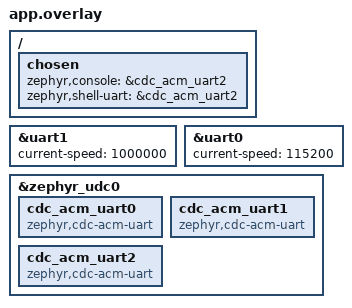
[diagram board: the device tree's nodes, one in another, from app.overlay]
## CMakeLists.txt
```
# SPDX-License-Identifier: MIT
#
# DECT mesh BLE relay (Thingy:91 X nRF5340): L2CAP CoC <-> inter-chip UART.
# Consumes 9P4Z as a Zephyr module (9P session pools, sysfs, DFU):
#   west build -b thingy91x/nrf5340/cpuapp . --sysbuild -- \
#     -DZEPHYR_EXTRA_MODULES=/Users/jrsharp/src/9p4z

cmake_minimum_required(VERSION 3.20.0)

find_package(Zephyr REQUIRED HINTS $ENV{ZEPHYR_BASE})
project(dect_relay)

target_sources(app PRIVATE src/main.c src/aether_conv_transport.c)
```

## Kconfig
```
# dect_relay — nRF5340 9P/USB aggregator application configuration

menu "dect_relay (nRF5340 9P/USB aggregator)"

# Per-module log level. Defaults to LOG_DEFAULT_LEVEL (INF), at which the verbose
# 9151-link diagnostics (mesh RX deliver / post-Tversion / post-Twalk / walk
# hexdump) -- which are LOG_DBG -- compile out entirely. Set
# CONFIG_DECT_RELAY_LOG_LEVEL_DBG=y to bring them back when debugging the link.
module = DECT_RELAY
module-str = dect_relay
source "$(ZEPHYR_BASE)/subsys/logging/Kconfig.template.log_config"

menu "Zephyr Kernel"
source "Kconfig.zephyr"
endmenu

endmenu
```

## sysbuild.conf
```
# Build the nRF5340 network-core image as a Bluetooth HCI controller (IPC radio),
# so the application core's BLE host has a controller to talk to.
SB_CONFIG_NETCORE_IPC_RADIO=y
SB_CONFIG_NETCORE_IPC_RADIO_BT_HCI_IPC=y
```

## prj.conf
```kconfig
# nRF5340 BLE relay: a transparent byte pump between a Bluetooth LE L2CAP
# connection-oriented channel (no custom GATT) and the inter-chip UART (uart1)
# carrying the nRF9151's 9P /net/aether server.

# --- Bluetooth LE peripheral + L2CAP CoC -----------------------------------
CONFIG_BT=y
CONFIG_BT_PERIPHERAL=y
CONFIG_BT_DEVICE_NAME="DECTstrous GW"
# Legacy connectable advertising: 9P-over-L2CAP clients (iOS scanner, 9p4z
# l2cap_client) discover the gateway via the 9PIS service UUID, which fits the
# 31-byte legacy AD (flags + 128-bit UUID = 21 B). No extended adv -> no net-core
# controller change, so this rides the app-core dev/fw5340 OTA.
# L2CAP CoC requires the SMP module to be present (BT_L2CAP_DYNAMIC_CHANNEL
# depends on BT_SMP). The link itself is left open (sec_level L1); the 9PIS
# chars and the 9P service need no pairing/bonding (per the gateway brief).
CONFIG_BT_SMP=y
CONFIG_BT_BONDABLE=n
CONFIG_BT_L2CAP_DYNAMIC_CHANNEL=y
# L2CAP SDU MTU. NCS clamps this to ~65 if pushed past what the ACL buffers allow
# (and treats the clamp as a fatal Kconfig warning), so keep it at 512 -- plenty
# for a /net/aether datagram (~471 B 9P message). The 9PIS transport_info still
# advertises mtu=4096 as the service ceiling; the CoC channel negotiates the real
# MTU (512) at connect, so the client just over-allocates its RX buffer. The RX
# side sets a matching rx.mtu + alloc_buf in 9p4z session_pool_l2cap.
CONFIG_BT_L2CAP_TX_MTU=512
CONFIG_BT_BUF_ACL_RX_SIZE=251
CONFIG_BT_BUF_ACL_TX_SIZE=251
CONFIG_BT_DATA_LEN_UPDATE=y
CONFIG_BT_AUTO_PHY_UPDATE=y

# --- 9P Information Service (9PIS) GATT + PSM ------------------------------
# The 9PIS GATT service lets clients read the PSM/MTU/features and connect with
# zero config; the service UUID is advertised so they can filter on it. PSM
# 0x0080 (=128) is the value clients expect for the 9P L2CAP service.
CONFIG_NINEP_GATT_9PIS=y
CONFIG_NINEP_L2CAP_PSM=0x0080

# --- Inter-chip UART (interrupt-driven) + ring buffer ----------------------
CONFIG_SERIAL=y
CONFIG_UART_INTERRUPT_DRIVEN=y
CONFIG_RING_BUFFER=y
# GPIO: we drive the 9151's reset line (P1.07) to bring it out of reset at boot.
CONFIG_GPIO=y

# --- USB CDC ACM: surface the nRF9151 console (its uart0 -> our uart0) over USB
# so the host can drive the 9151 shell (dect bands/info/cad) and read mesh logs.
# Descriptors mirror the stock connectivity_bridge so existing host tooling/udev
# rules recognize it (Nordic VID 0x1915 / "Thingy:91 X UART" PID). --------------
CONFIG_USB_DEVICE_STACK=y
CONFIG_USB_DEVICE_MANUFACTURER="Nordic Semiconductor"
CONFIG_USB_DEVICE_PRODUCT="DECT Aether Relay"
CONFIG_USB_DEVICE_VID=0x1915
CONFIG_USB_DEVICE_PID=0x910A
CONFIG_USB_MAX_POWER=250
CONFIG_USB_CDC_ACM=y
CONFIG_USB_CDC_ACM_RINGBUF_SIZE=2048
# Composite: 3 CDC ACM ports (9151 console / 9P / 5340 console). More USB
# transfer slots so the 3 endpoints don't exhaust the pool (was flooding
# "usb_transfer: No transfer slot available").
CONFIG_USB_COMPOSITE_DEVICE=y
CONFIG_USB_MAX_NUM_TRANSFERS=8

# --- 9P server: firmware-as-files over the 2nd USB CDC (Phase 2) -------------
# A 9p4z server on cdc_acm_uart1 exposing an MCUboot DFU node so the host can
# `9p write /dev/fw5340` to self-update the 5340 in situ. Phase 3 adds a client
# link to the 9151 + union_fs to re-export /dev/fw9151 + /net/aether here too.
CONFIG_NINEP=y
CONFIG_NINEP_SERVER=y
# DTR-gated session pool over CDC-ACM: a fresh 9P session (RX state + fid
# namespace) per host open/close, so the server no longer wedges when a stream
# client reconnects. Each session's recv handler runs on a dedicated work queue
# (interrupt-driven RX feeds it), not the UART ISR. Shares fs_ops with the L2CAP
# session pool below for a multi-transport re-export server.
CONFIG_NINEP_SESSION_POOL_UART=y
# Re-export the SAME fw_sysfs over BLE L2CAP CoC as well (PSM RELAY_PSM). Same
# /dev tree, second transport -- 9P's transport-agnostic story, made literal.
# (Depends on BT_L2CAP_DYNAMIC_CHANNEL, already enabled above.)
CONFIG_NINEP_TRANSPORT_L2CAP=y
# --- 9P CLIENT to the 9151 over uart1 (the aggregator link) -----------------
# The 5340 is a 9P client to the 9151's server (its uart0 <-> our uart1), so it
# can re-export the 9151's /dev/firmware as /dev/fw9151. RX uses DEFERRED_RX
# (interrupt ISR -> byte ring -> framer thread), NOT the old POLLING mode: that
# was a lowest-priority busy-poll that got STARVED under BLE+USB+chat load, so it
# missed uart1 RX bytes -> the 9P framing desynced -> the host saw "read failed" /
# one-sided chat / flaky sessions. With DEFERRED_RX the ISR catches every byte
# into the ring (hardware-priority), and only framer-thread lag (absorbed by the
# ring) can ever drop -- the same fix the 9151 side already made. recv_cb still
# runs in thread context (the framer thread), so the condvar-broadcast rule holds.
CONFIG_NINEP_CLIENT=y
CONFIG_NINEP_TRANSPORT_UART=y
CONFIG_NINEP_UART_DEFERRED_RX=y
CONFIG_NINEP_UART_POLLING_STACK_SIZE=8192
# Ring >= one max message (msize 8192) + slack, so a full pipelined reply can be
# absorbed while the framer thread is briefly preempted.
CONFIG_NINEP_UART_DEFERRED_RX_RING_SIZE=12288
CONFIG_NINEP_DFU=y
# Transparent proxy backend: re-export the 9151's dynamic /net/aether datagram
# tree (clone/ctl/data conversations) as a local mount, so host/L2CAP 9P clients
# reach it through the same server that serves /dev/fw9151. Each host fid keeps a
# persistent 1:1 mapping to a 9151 client fid (clone allocates upstream on walk).
CONFIG_NINEP_REMOTE_FS=y
# Async (worker-dispatched) reads: a host read of /net/aether `data` forwards
# over the mesh client and blocks until a datagram arrives; without this it would
# stall the session-pool processing thread (freezing the USB 9P server for other
# requests). The worker runs the forwarding client_read off that thread. Its
# stack must hold ninep_client_read's ~2KB reply buffer, so widen it to 4096.
CONFIG_NINEP_SERVER_ASYNC_READ=y
CONFIG_NINEP_SERVER_ASYNC_READ_WORKERS=4
CONFIG_NINEP_SERVER_ASYNC_READ_STACK=4096
# Headroom: each re-exported /net/aether fid consumes one mesh-client fid (on top
# of the base-path fid + the OTA write fid), so widen the client fid pool.
CONFIG_NINEP_MAX_FIDS=48
# Server-side fid table. The default (32) is exhausted by 9pfuse: macOS holds a
# fid per FUSE-cached inode and re-looks-up files as entry_valid lapses WITHOUT
# ever sending Forget, so held fids accumulate (~1 per read) until Twalk hits
# "cannot allocate newfid" (which 9pfuse surfaces as "Result too large" after
# ~28 reads). Stock `9p` clunks promptly and never gets near this. Give a big
# pool so realistic 9pfuse sessions don't exhaust before macOS reclaims inodes.
CONFIG_NINEP_SERVER_MAX_FIDS=256
CONFIG_NINEP_MAX_MESSAGE_SIZE=8192
# MCUboot image management for DFU (the bootloader itself comes from sysbuild).
CONFIG_IMG_MANAGER=y
# Erase the secondary slot a page at a time as the image streams in, NOT one
# long up-front erase. On nRF53 a flash erase stalls instruction fetch, so the
# whole-slot erase blocked USB for seconds -> the relay fell into MCUboot
# mid-write. Progressive erase also makes flash_img own the (correct) secondary.
CONFIG_IMG_ERASE_PROGRESSIVELY=y
CONFIG_STREAM_FLASH=y
CONFIG_FLASH=y
CONFIG_FLASH_MAP=y
CONFIG_REBOOT=y

# --- 5340 console -> USB CDC (cdc_acm_uart2); RTT kept as a 2nd log backend --
# Console + log go to cdc_acm_uart2 (chosen zephyr,console). Logs ALSO go to RTT
# as a fallback (DK path + the early boot before USB enumerates). So the relay's
# own log is finally readable over USB -- no DK/RTT required to debug it.
CONFIG_UART_CONSOLE=y
CONFIG_RTT_CONSOLE=n
CONFIG_UART_LINE_CTRL=y
CONFIG_LOG=y
# The interactive shell now owns cdc_acm_uart2 (zephyr,shell-uart), so logs go out
# via the SHELL's log backend (CONFIG_SHELL_LOG_BACKEND, default y) interleaved with
# the prompt. Drop the standalone UART log backend or every line double-prints on
# CDC2. RTT stays as a 2nd backend (J-Link + early boot before the shell is up).
CONFIG_LOG_BACKEND_UART=n
CONFIG_USE_SEGGER_RTT=y
CONFIG_LOG_BACKEND_RTT=y
# Verbose 9151-link diagnostics (mesh RX deliver / post-Tversion / post-Twalk /
# walk hexdump) are LOG_DBG and compile out at the default INF level. Uncomment
# to bring them back when debugging the uart1 link (see app Kconfig):
# CONFIG_DECT_RELAY_LOG_LEVEL_DBG=y

# Boot-banner app name (default was "My Application"); version comes from VERSION.
CONFIG_NCS_APPLICATION_BOOT_BANNER_STRING="DECTstrous Relay"
# MCUboot image version so a self-OTA swap is verifiable (current/pending in
# /dev/fw5340); keep in sync with VERSION above.
CONFIG_MCUBOOT_IMGTOOL_SIGN_VERSION="0.38.31+0"

# --- Memfault: coredump + reboot-reason capture, exported over the 5340 console -
# The relay should report to the Memfault fleet, and right now this is how we catch
# the DFU-write crash: Memfault captures a coredump (faulting PC + stack) and the
# reboot reason across the reset. On the next boot, `mflt export` dumps them as
# base64 chunks over this console (cdc2) for offline decode / upload.
CONFIG_MEMFAULT=y
CONFIG_MEMFAULT_NCS_PROJECT_KEY=""
CONFIG_MEMFAULT_NCS_FW_TYPE="dect-relay-5340"
# Report the real build version (VERSION file) -- leave FW_VERSION unset so it
# defaults to $(APP_VERSION_TWEAK_STRING) instead of a hardcoded string.
CONFIG_MEMFAULT_NCS_FW_VERSION_STATIC=y
CONFIG_MEMFAULT_NCS_HW_VERSION="thingy91x"
CONFIG_MEMFAULT_NCS_DEVICE_ID_RUNTIME=y
# Emit a heartbeat (metrics chunk) every 60s like the 9151, so the relay device
# reports regularly instead of on the NCS default ~1h interval.
CONFIG_MEMFAULT_METRICS_HEARTBEAT_INTERVAL_SECS=60
# RAM-backed coredump survives the warm (fault) reset; reboot reason is read from
# RESETREAS at boot, so it survives even a brownout.
CONFIG_MEMFAULT_RAM_BACKED_COREDUMP=y
# Interactive Zephyr shell + the `mflt` debug shell (provides `mflt export`).
CONFIG_SHELL=y
CONFIG_MEMFAULT_SHELL=y

# --- System ----------------------------------------------------------------
# 9P server TX buffer (NINEP_MAX_MESSAGE_SIZE=8192) is heap-allocated; the
# re-export will add a client too. 16K ENOMEM'd it alongside BT+USB -> give room.
CONFIG_HEAP_MEM_POOL_SIZE=49152
CONFIG_MAIN_STACK_SIZE=2048
# DFU-write lockup debug: HW_STACK_PROTECTION guards thread stacks but the
# MSP/ISR stack was unguarded -> an overflow during the deep flash write escalated
# to a CPU lockup (RESETREAS bit4) with no handler/coredump. Guard the main stack
# so it faults (Memfault catches it) instead, and give the 9P work queue room for
# the flash_img -> soc_flash_nrf chain.
CONFIG_MPU_STACK_GUARD=y
CONFIG_NINEP_SESSION_PROC_STACK_SIZE=16384
```

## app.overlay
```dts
/*
 * Relay overlay. Inter-chip links to the nRF9151: uart1 (9P /net/aether) and
 * uart0 (the 9151's console/shell). Three USB CDC ACM ports front it all:
 *   cdc0 = 9151 console   cdc1 = 9P   cdc2 = the 5340's OWN console.
 */

/ {
	chosen {
		zephyr,console = &cdc_acm_uart2;     /* relay's own log -> USB (CDC2) */
		zephyr,shell-uart = &cdc_acm_uart2;  /* interactive shell on CDC2 too
						      * (board default was &rtt0 = J-Link only) */
	};
};

/* 9151 9P transport (its uart1) -> BLE L2CAP. */
&uart1 {
	status = "okay";
	/* Inter-chip 9P link to the nRF9151. 1 Mbps -- MUST match the 9151 side
	 * (dect_mesh app.overlay); flash both together or the link breaks. */
	current-speed = <1000000>;
};

/* 9151 console/shell (its uart0) -> USB CDC ACM. */
&uart0 {
	status = "okay";
	current-speed = <115200>;
};

/* Composite USB: THREE CDC ACM ports (max on nRF5340: 2 IN + 1 OUT eps each).
 *   cdc_acm_uart0 -> 9151 console/shell (byte-pump from uart0)
 *   cdc_acm_uart1 -> 9P (aggregator re-export server / pump to the 9151)
 *   cdc_acm_uart2 -> the 5340's OWN console (this relay's log over USB)
 * The board defines &usbd (nordic,nrf-usbd); we add the CDC ACM functions. */
&zephyr_udc0 {
	cdc_acm_uart0: cdc_acm_uart0 {
		compatible = "zephyr,cdc-acm-uart";
	};
	cdc_acm_uart1: cdc_acm_uart1 {
		compatible = "zephyr,cdc-acm-uart";
	};
	cdc_acm_uart2: cdc_acm_uart2 {
		compatible = "zephyr,cdc-acm-uart";
	};
};
```

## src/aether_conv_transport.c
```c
/*
 * aether_conv_transport -- see aether_conv_transport.h and doc/MESH_REMOTE_MOUNT.md.
 *
 * Layering (bottom to top):
 *   carrier mesh_client (UART) -> 9151 /net/aether conversation <conv>
 *      ctl_fid  : net/aether/clone   (held open; `connect <peer>` written here)
 *      data_fid : net/aether/<conv>/data  (one framed 9P msg written, reply read)
 *   this transport: send(T) -> pump writes data_fid, reads reply (retry+tag-match)
 *   nested ninep_client: Tversion/attach/walk/... to the REMOTE node's 9P server
 */
#include "aether_conv_transport.h"

#include <zephyr/logging/log.h>
#include <zephyr/9p/protocol.h>
#include <string.h>
#include <stdlib.h>
#include <stdio.h>

LOG_MODULE_REGISTER(aether_conv_tp, LOG_LEVEL_INF);

/* The pump runs the CARRIER ninep_client write+read AND the nested client's
 * recv_cb decode (recv_cb fires on this thread) -- the same class of work the
 * relay's proxy work queue gets 16384 for. 2048 overflowed the MPU stack guard
 * on the first /net/mesh access (fault -> reboot); 8192 gives comfortable
 * headroom for one carrier round-trip + the nested R decode. */
#define PUMP_STACK 8192
#define TX_ATTEMPTS 8   /* resend a lost T this many times (do_bridge used 4 on USB) */
#define RX_POLLS    6   /* reads per attempt while awaiting the reply datagram */
#define RX_POLL_MS  30  /* gap before re-reading an empty data fid (mesh round-trip) */

static K_THREAD_STACK_DEFINE(pump_stack, PUMP_STACK);

static inline uint16_t tag16(const uint8_t *m) { return (uint16_t)(m[5] | (m[6] << 8)); }

/* ---- ninep_transport ops ------------------------------------------------ */

static int aether_tx_send(struct ninep_transport *tr, const uint8_t *buf, size_t len)
{
	struct aether_conv_transport *t = CONTAINER_OF(tr, struct aether_conv_transport, transport);

	if (len < 7 || len > sizeof(t->txbuf)) {
		return -EMSGSIZE;
	}
	/* Copy: the nested client's tx_buf is only valid for this call; the pump
	 * runs asynchronously. The nested client is request-response (one T in
	 * flight -- the mesh 9P server is one-T-in-flight), so txbuf is never
	 * overwritten mid-pump. */
	memcpy(t->txbuf, buf, len);
	t->txlen = len;
	k_sem_give(&t->tx_sem);
	return (int)len;
}

static int aether_tx_start(struct ninep_transport *tr) { ARG_UNUSED(tr); return 0; }
static int aether_tx_stop(struct ninep_transport *tr)  { ARG_UNUSED(tr); return 0; }
static int aether_tx_mtu(struct ninep_transport *tr)   { ARG_UNUSED(tr); return AETHER_CONV_MTU; }

static const struct ninep_transport_ops aether_tx_ops = {
	.send = aether_tx_send,
	.start = aether_tx_start,
	.stop = aether_tx_stop,
	.get_mtu = aether_tx_mtu,
};

/* ---- the pump: do_bridge's inner loop, over the carrier client ---------- */

static void pump_fn(void *a, void *b, void *c)
{
	struct aether_conv_transport *t = a;
	ARG_UNUSED(b); ARG_UNUSED(c);

	for (;;) {
		k_sem_take(&t->tx_sem, K_FOREVER);

		k_mutex_lock(&t->lock, K_FOREVER);
		bool conn = t->connected;
		uint32_t dfid = t->data_fid;
		k_mutex_unlock(&t->lock);

		int rn = -1;

		if (!conn) {
			LOG_WRN("send with no conversation; nested client will time out");
			continue;
		}

		uint16_t want = tag16(t->txbuf);

		for (int attempt = 0; attempt < TX_ATTEMPTS && rn <= 0; attempt++) {
			int w = ninep_client_write(t->carrier, dfid, 0, t->txbuf, t->txlen);
			if (w < 0) {
				LOG_DBG("carrier write failed: %d (attempt %d)", w, attempt);
				continue;
			}
			/* Await the reply datagram: the 9151 surfaces it as readable data on
			 * the same data fid once it returns over the mesh. Poll a few times
			 * (round-trip latency), tag-matching to discard stale/duplicate R's
			 * on the untagged datagram stream. */
			for (int poll = 0; poll < RX_POLLS; poll++) {
				int r = ninep_client_read(t->carrier, dfid, 0, t->rb, sizeof(t->rb));
				if (r >= 7 && tag16(t->rb) == want) { rn = r; break; }
				if (r >= 7) {
					LOG_DBG("discard stale R tag=%u (want %u)", tag16(t->rb), want);
					continue;   /* another reply may be queued behind it */
				}
				k_msleep(RX_POLL_MS);   /* nothing yet -- let the round-trip land */
			}
		}

		if (rn > 0) {
			t->transport.recv_cb(&t->transport, t->rb, (size_t)rn,
					     t->transport.user_data);
		} else {
			LOG_WRN("mesh round-trip failed after retries (T type=%u tag=%u)",
				t->txbuf[4], want);
			/* No recv_cb -> nested client times out on this tag and reports it. */
		}
	}
}

/* ---- conversation setup (lifted from tools/aether_conv.c do_bridge) ------ */

void aether_conv_transport_disconnect(struct aether_conv_transport *t)
{
	k_mutex_lock(&t->lock, K_FOREVER);
	if (t->connected) {
		if (t->data_fid != NINEP_NOFID) (void)ninep_client_clunk(t->carrier, t->data_fid);
		if (t->ctl_fid != NINEP_NOFID)  (void)ninep_client_clunk(t->carrier, t->ctl_fid);
	}
	t->data_fid = NINEP_NOFID;
	t->ctl_fid = NINEP_NOFID;
	t->conv = -1;
	t->connected = false;
	k_mutex_unlock(&t->lock);
}

int aether_conv_transport_connect(struct aether_conv_transport *t,
				  uint32_t carrier_root, const char *peer)
{
	int ret;

	k_mutex_lock(&t->lock, K_FOREVER);
	if (t->connected && strcmp(t->peer, peer) == 0) {
		k_mutex_unlock(&t->lock);
		return 0;   /* already connected to this peer */
	}
	k_mutex_unlock(&t->lock);

	aether_conv_transport_disconnect(t);   /* drop any prior conversation */

	uint32_t ctl_fid = NINEP_NOFID, data_fid = NINEP_NOFID;

	/* walk net/aether/clone, open, read the allocated conversation number */
	ret = ninep_client_walk(t->carrier, carrier_root, &ctl_fid, "net/aether/clone");
	if (ret < 0) { LOG_WRN("walk clone: %d", ret); goto fail; }
	ret = ninep_client_open(t->carrier, ctl_fid, NINEP_ORDWR);
	if (ret < 0) { LOG_WRN("open clone: %d", ret); goto fail; }

	uint8_t nb[16];
	int n = ninep_client_read(t->carrier, ctl_fid, 0, nb, sizeof(nb) - 1);
	if (n <= 0) { LOG_WRN("read conv#: %d", n); ret = -EIO; goto fail; }
	nb[n] = 0;
	int conv = atoi((char *)nb);

	/* walk net/aether/<conv>/data, open read-write */
	char path[48];
	snprintf(path, sizeof(path), "net/aether/%d/data", conv);
	ret = ninep_client_walk(t->carrier, carrier_root, &data_fid, path);
	if (ret < 0) { LOG_WRN("walk data: %d", ret); goto fail; }
	ret = ninep_client_open(t->carrier, data_fid, NINEP_ORDWR);
	if (ret < 0) { LOG_WRN("open data: %d", ret); goto fail; }

	/* connect the conversation to the target peer (written to the ctl fid) */
	char cmd[40];
	int l = snprintf(cmd, sizeof(cmd), "connect %s", peer);
	ret = ninep_client_write(t->carrier, ctl_fid, 0, (const uint8_t *)cmd, l);
	if (ret < 0) { LOG_WRN("ctl connect: %d", ret); goto fail; }

	k_mutex_lock(&t->lock, K_FOREVER);
	t->ctl_fid = ctl_fid;
	t->data_fid = data_fid;
	t->conv = conv;
	strncpy(t->peer, peer, sizeof(t->peer) - 1);
	t->peer[sizeof(t->peer) - 1] = 0;
	t->connected = true;
	k_mutex_unlock(&t->lock);

	LOG_INF("conversation %d connected to %s (ctl fid %u, data fid %u)",
		conv, peer, ctl_fid, data_fid);
	return 0;

fail:
	if (data_fid != NINEP_NOFID) (void)ninep_client_clunk(t->carrier, data_fid);
	if (ctl_fid != NINEP_NOFID)  (void)ninep_client_clunk(t->carrier, ctl_fid);
	return ret;
}

int aether_conv_transport_init(struct aether_conv_transport *t,
			       struct ninep_client *carrier)
{
	memset(t, 0, sizeof(*t));
	t->carrier = carrier;
	t->conv = -1;
	t->ctl_fid = NINEP_NOFID;
	t->data_fid = NINEP_NOFID;
	t->transport.ops = &aether_tx_ops;
	t->transport.priv_data = NULL;

	k_mutex_init(&t->lock);
	k_sem_init(&t->tx_sem, 0, 1);

	k_thread_create(&t->pump_thread, pump_stack, K_THREAD_STACK_SIZEOF(pump_stack),
			pump_fn, t, NULL, NULL, K_PRIO_PREEMPT(7), 0, K_NO_WAIT);
	k_thread_name_set(&t->pump_thread, "aether_tp_pump");
	return 0;
}
```

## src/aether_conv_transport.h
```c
/*
 * aether_conv_transport -- a 9p4z ninep_transport that carries a NESTED 9P
 * client's messages over the DECT mesh, by tunneling them through a held
 * /net/aether conversation on the 9151 (reached via the relay's EXISTING
 * mesh_client over the inter-chip UART).
 *
 * This is the on-device home of tools/aether_conv --bridge: the 9151 does the
 * radio + HONR hop-routing; this transport only frames one 9P message per
 * reliable datagram and applies do_bridge's retry + tag-match. Feed it to a
 * second ninep_client + remote_fs so the relay can re-export a REMOTE node's
 * filesystem (aether!<addr>) to L2CAP/USB clients (e.g. a macOS 9pfuse mount).
 *
 * See doc/MESH_REMOTE_MOUNT.md.
 */
#ifndef AETHER_CONV_TRANSPORT_H_
#define AETHER_CONV_TRANSPORT_H_

#include <zephyr/kernel.h>
#include <zephyr/9p/transport.h>
#include <zephyr/9p/client.h>

/* Max single 9P message == one mesh datagram. Kept <= the 9151's AETHER_MAX_PAYLOAD
 * so every tunneled T/R fits one reliable unicast with no reassembly. */
#define AETHER_CONV_MTU 448

struct aether_conv_transport {
	struct ninep_transport transport;   /* embedded; client_init fills recv_cb/user_data */
	struct ninep_client *carrier;       /* OUTER client to the 9151 (UART) */

	/* Held /net/aether conversation on the 9151 (carrier fids). */
	struct k_mutex lock;                /* guards the conversation state below */
	uint32_t ctl_fid;                   /* net/aether/clone, held open == the ctl fid */
	uint32_t data_fid;                  /* net/aether/<conv>/data */
	int conv;                           /* conversation number (-1 = none) */
	bool connected;
	char peer[24];                      /* current target addr string */

	/* TX pump: send() hands a framed T here; the pump does the carrier
	 * write/read (retry + tag-match) and delivers the R via recv_cb -- off the
	 * caller's stack so the nested client is already waiting when recv_cb fires
	 * (same reason the UART transport defers RX to a workqueue). */
	struct k_sem tx_sem;
	uint8_t txbuf[AETHER_CONV_MTU + 16];
	size_t txlen;
	uint8_t rb[AETHER_CONV_MTU + 16];
	int rn;                             /* pump result: reply length, or <=0 on failure */
	struct k_thread pump_thread;
};

/*
 * Initialize the transport and start its pump thread. @carrier is the relay's
 * already-inited mesh_client (must be attached before connect()). After this,
 * pass &t->transport to ninep_client_init() for the nested client.
 */
int aether_conv_transport_init(struct aether_conv_transport *t,
			       struct ninep_client *carrier);

/*
 * (Re)open a /net/aether conversation on the 9151 and `connect` it to @peer.
 * @carrier_root is the live 9151 root fid (from mesh_ensure_attached). Idempotent
 * for the same peer; switching peers drops the old conversation first.
 */
int aether_conv_transport_connect(struct aether_conv_transport *t,
				  uint32_t carrier_root, const char *peer);

/* Clunk the conversation fids and mark disconnected (next connect() reopens). */
void aether_conv_transport_disconnect(struct aether_conv_transport *t);

#endif /* AETHER_CONV_TRANSPORT_H_ */
```
